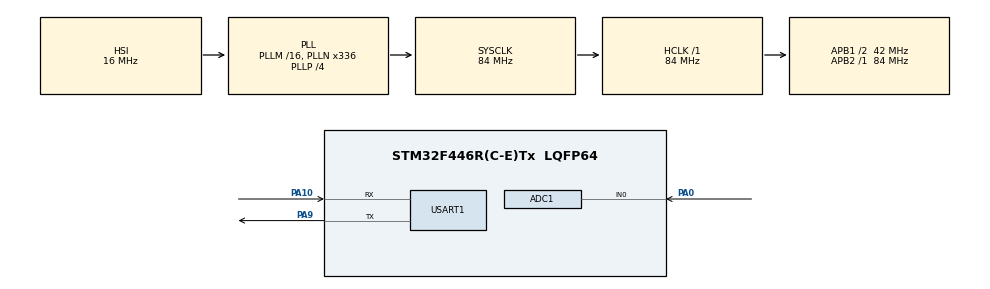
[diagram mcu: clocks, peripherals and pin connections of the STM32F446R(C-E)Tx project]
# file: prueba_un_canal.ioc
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ADC1.Channel-0\#ChannelRegularConversion=ADC_CHANNEL_0
ADC1.NbrOfConversion=1
ADC1.NbrOfConversionFlag=1
ADC1.Rank-0\#ChannelRegularConversion=1
ADC1.SamplingTime-0\#ChannelRegularConversion=ADC_SAMPLETIME_84CYCLES
ADC1.ScanConvMode=DISABLE
ADC1.master=1
Mcu.Family=STM32F4
Mcu.Name=STM32F446R(C-E)Tx
Mcu.Package=LQFP64
NVIC.ADC_IRQn=true\:0\:0\:false\:false\:true\:true
NVIC.PriorityGroup=NVIC_PRIORITYGROUP_0
PA0-WKUP.Signal=ADCx_IN0
PA10.Mode=Asynchronous
PA10.Signal=USART1_RX
PA13.GPIO_Label=TMS
PA13.Mode=Serial_Wire
PA13.Signal=SYS_JTMS-SWDIO
PA14.GPIO_Label=TCK
PA14.Mode=Serial_Wire
PA14.Signal=SYS_JTCK-SWCLK
PA9.Mode=Asynchronous
PA9.Signal=USART1_TX
PB3.GPIO_Label=SWO
PB3.Signal=SYS_JTDO-SWO
PC14-OSC32_IN.Mode=LSE-External-Oscillator
PC14-OSC32_IN.Signal=RCC_OSC32_IN
PC15-OSC32_OUT.Mode=LSE-External-Oscillator
PC15-OSC32_OUT.Signal=RCC_OSC32_OUT
PH0-OSC_IN.Mode=HSE-External-Oscillator
PH0-OSC_IN.Signal=RCC_OSC_IN
PH1-OSC_OUT.Mode=HSE-External-Oscillator
PH1-OSC_OUT.Signal=RCC_OSC_OUT
ProjectManager.HeapSize=0x200
ProjectManager.StackSize=0x400
ProjectManager.TargetToolchain=TrueSTUDIO
RCC.48MHZClocksFreq_Value=84000000
RCC.AHBFreq_Value=84000000
RCC.APB1CLKDivider=RCC_HCLK_DIV2
RCC.APB1Freq_Value=42000000
RCC.APB1TimFreq_Value=84000000
RCC.APB2Freq_Value=84000000
RCC.APB2TimFreq_Value=84000000
RCC.CortexFreq_Value=84000000
RCC.FLatency-AdvancedSettings=FLASH_LATENCY_2
RCC.HCLKFreq_Value=84000000
RCC.HSE_VALUE=8000000
RCC.HSI_VALUE=16000000
RCC.PLLN=336
RCC.PLLP=RCC_PLLP_DIV4
RCC.SYSCLKFreq_VALUE=84000000
RCC.SYSCLKSource=RCC_SYSCLKSOURCE_PLLCLK
RCC.USBFreq_Value=168000000
RCC.VCOOutputFreq_Value=336000000
SH.ADCx_IN0.0=ADC1_IN0,IN0
USART1.VirtualMode=VM_ASYNC
board=NUCLEO-F446RE

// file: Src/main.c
/**
  ******************************************************************************
  * @file           : main.c
  * @brief          : Main program body
  ******************************************************************************
  ** This notice applies to any and all portions of this file
  * that are not between comment pairs USER CODE BEGIN and
  * USER CODE END. Other portions of this file, whether
  * inserted by the user or by software development tools
  * are owned by their respective copyright owners.
  *
  * COPYRIGHT(c) 2018 STMicroelectronics
  *
  * Redistribution and use in source and binary forms, with or without modification,
  * are permitted provided that the following conditions are met:
  *   1. Redistributions of source code must retain the above copyright notice,
  *      this list of conditions and the following disclaimer.
  *   2. Redistributions in binary form must reproduce the above copyright notice,
  *      this list of conditions and the following disclaimer in the documentation
  *      and/or other materials provided with the distribution.
  *   3. Neither the name of STMicroelectronics nor the names of its contributors
  *      may be used to endorse or promote products derived from this software
  *      without specific prior written permission.
  *
  * THIS SOFTWARE IS PROVIDED BY THE COPYRIGHT HOLDERS AND CONTRIBUTORS "AS IS"
  * AND ANY EXPRESS OR IMPLIED WARRANTIES, INCLUDING, BUT NOT LIMITED TO, THE
  * IMPLIED WARRANTIES OF MERCHANTABILITY AND FITNESS FOR A PARTICULAR PURPOSE ARE
  * DISCLAIMED. IN NO EVENT SHALL THE COPYRIGHT HOLDER OR CONTRIBUTORS BE LIABLE
  * FOR ANY DIRECT, INDIRECT, INCIDENTAL, SPECIAL, EXEMPLARY, OR CONSEQUENTIAL
  * DAMAGES (INCLUDING, BUT NOT LIMITED TO, PROCUREMENT OF SUBSTITUTE GOODS OR
  * SERVICES; LOSS OF USE, DATA, OR PROFITS; OR BUSINESS INTERRUPTION) HOWEVER
  * CAUSED AND ON ANY THEORY OF LIABILITY, WHETHER IN CONTRACT, STRICT LIABILITY,
  * OR TORT (INCLUDING NEGLIGENCE OR OTHERWISE) ARISING IN ANY WAY OUT OF THE USE
  * OF THIS SOFTWARE, EVEN IF ADVISED OF THE POSSIBILITY OF SUCH DAMAGE.
  *
  ******************************************************************************
  */
#include "main.h"
#include "stm32f4xx_hal.h"

/* USER CODE BEGIN Includes */
#include <stdio.h>
#include <math.h>
/* USER CODE END Includes */

ADC_HandleTypeDef hadc1;

UART_HandleTypeDef huart1;

/* USER CODE BEGIN PV */
/* Private variables ---------------------------------------------------------*/
uint16_t adc_value;
float voltage;
/* USER CODE END PV */

void SystemClock_Config(void);
static void MX_GPIO_Init(void);
static void MX_ADC1_Init(void);
static void MX_USART1_UART_Init(void);
void ftoa(float n, char *str, int len);

/* USER CODE BEGIN PFP */
/* Private function prototypes -----------------------------------------------*/

/* USER CODE END PFP */
char res[6];
/* USER CODE BEGIN 0 */
void HAL_ADC_ConvCpltCallback(ADC_HandleTypeDef* hadc1)
{
	adc_value = HAL_ADC_GetValue(hadc1);
	 //voltage=3.3000*(adc_value/4096.0000);
	 //ftoa(voltage, res, 3);
	 printf("#%d\r\n",adc_value);
	 //HAL_Delay(1);

	HAL_ADC_Start_IT(hadc1); // Re-Start ADC1 under Interrupt
	                         // this is necessary because we don'use
	                         // the Continuos Conversion Mode
}

/* USER CODE END 0 */

int main(void)
{

  /* MCU Configuration----------------------------------------------------------*/

  /* Reset of all peripherals, Initializes the Flash interface and the Systick. */
  HAL_Init();

  /* Configure the system clock */
  SystemClock_Config();

  /* Initialize all configured peripherals */
  MX_GPIO_Init();
  MX_ADC1_Init();
  MX_USART1_UART_Init();
  /* USER CODE BEGIN 2 */

  HAL_ADC_Start_IT(&hadc1);
  /* USER CODE END 2 */

  /* Infinite loop */
  while (1)
  {

  }

}

void SystemClock_Config(void)
{

  RCC_OscInitTypeDef RCC_OscInitStruct;
  RCC_ClkInitTypeDef RCC_ClkInitStruct;

    /**Configure the main internal regulator output voltage
    */
  __HAL_RCC_PWR_CLK_ENABLE();

  __HAL_PWR_VOLTAGESCALING_CONFIG(PWR_REGULATOR_VOLTAGE_SCALE3);

    /**Initializes the CPU, AHB and APB busses clocks
    */
  RCC_OscInitStruct.OscillatorType = RCC_OSCILLATORTYPE_HSI;
  RCC_OscInitStruct.HSIState = RCC_HSI_ON;
  RCC_OscInitStruct.HSICalibrationValue = 16;
  RCC_OscInitStruct.PLL.PLLState = RCC_PLL_ON;
  RCC_OscInitStruct.PLL.PLLSource = RCC_PLLSOURCE_HSI;
  RCC_OscInitStruct.PLL.PLLM = 16;
  RCC_OscInitStruct.PLL.PLLN = 336;
  RCC_OscInitStruct.PLL.PLLP = RCC_PLLP_DIV4;
  RCC_OscInitStruct.PLL.PLLQ = 2;
  RCC_OscInitStruct.PLL.PLLR = 2;
  if (HAL_RCC_OscConfig(&RCC_OscInitStruct) != HAL_OK)
  {
    _Error_Handler(__FILE__, __LINE__);
  }

    /**Initializes the CPU, AHB and APB busses clocks
    */
  RCC_ClkInitStruct.ClockType = RCC_CLOCKTYPE_HCLK|RCC_CLOCKTYPE_SYSCLK
                              |RCC_CLOCKTYPE_PCLK1|RCC_CLOCKTYPE_PCLK2;
  RCC_ClkInitStruct.SYSCLKSource = RCC_SYSCLKSOURCE_PLLCLK;
  RCC_ClkInitStruct.AHBCLKDivider = RCC_SYSCLK_DIV1;
  RCC_ClkInitStruct.APB1CLKDivider = RCC_HCLK_DIV2;
  RCC_ClkInitStruct.APB2CLKDivider = RCC_HCLK_DIV1;

  if (HAL_RCC_ClockConfig(&RCC_ClkInitStruct, FLASH_LATENCY_2) != HAL_OK)
  {
    _Error_Handler(__FILE__, __LINE__);
  }

    /**Configure the Systick interrupt time
    */
  HAL_SYSTICK_Config(HAL_RCC_GetHCLKFreq()/1000);

    /**Configure the Systick
    */
  HAL_SYSTICK_CLKSourceConfig(SYSTICK_CLKSOURCE_HCLK);

  /* SysTick_IRQn interrupt configuration */
  HAL_NVIC_SetPriority(SysTick_IRQn, 0, 0);
}

/* ADC1 init function */
static void MX_ADC1_Init(void)
{

  ADC_ChannelConfTypeDef sConfig;

    /**Configure the global features of the ADC (Clock, Resolution, Data Alignment and number of conversion)
    */
  hadc1.Instance = ADC1;
  hadc1.Init.ClockPrescaler = ADC_CLOCK_SYNC_PCLK_DIV4;
  hadc1.Init.Resolution = ADC_RESOLUTION_10B;
  hadc1.Init.ScanConvMode = DISABLE;
  hadc1.Init.ContinuousConvMode = DISABLE;
  hadc1.Init.DiscontinuousConvMode = DISABLE;
  hadc1.Init.ExternalTrigConvEdge = ADC_EXTERNALTRIGCONVEDGE_NONE;
  hadc1.Init.ExternalTrigConv = ADC_SOFTWARE_START;
  hadc1.Init.DataAlign = ADC_DATAALIGN_RIGHT;
  hadc1.Init.NbrOfConversion = 1;
  hadc1.Init.DMAContinuousRequests = DISABLE;
  hadc1.Init.EOCSelection = ADC_EOC_SINGLE_CONV;
  if (HAL_ADC_Init(&hadc1) != HAL_OK)
  {
    _Error_Handler(__FILE__, __LINE__);
  }

    /**Configure for the selected ADC regular channel its corresponding rank in the sequencer and its sample time.
    */
  sConfig.Channel = ADC_CHANNEL_0;
  sConfig.Rank = 1;
  sConfig.SamplingTime = ADC_SAMPLETIME_84CYCLES;
  if (HAL_ADC_ConfigChannel(&hadc1, &sConfig) != HAL_OK)
  {
    _Error_Handler(__FILE__, __LINE__);
  }

}

/* USART1 init function */
static void MX_USART1_UART_Init(void)
{

  huart1.Instance = USART1;
  huart1.Init.BaudRate = 115200;
  huart1.Init.WordLength = UART_WORDLENGTH_8B;
  huart1.Init.StopBits = UART_STOPBITS_1;
  huart1.Init.Parity = UART_PARITY_NONE;
  huart1.Init.Mode = UART_MODE_TX_RX;
  huart1.Init.HwFlowCtl = UART_HWCONTROL_NONE;
  huart1.Init.OverSampling = UART_OVERSAMPLING_16;
  if (HAL_UART_Init(&huart1) != HAL_OK)
  {
    _Error_Handler(__FILE__, __LINE__);
  }

}

/** Configure pins as
        * Analog
        * Input
        * Output
        * EVENT_OUT
        * EXTI
*/
static void MX_GPIO_Init(void)
{

  /* GPIO Ports Clock Enable */
  __HAL_RCC_GPIOC_CLK_ENABLE();
  __HAL_RCC_GPIOH_CLK_ENABLE();
  __HAL_RCC_GPIOA_CLK_ENABLE();
  __HAL_RCC_GPIOB_CLK_ENABLE();

}

/* USER CODE BEGIN 4 */
int __io_putchar(int ch)
{
 uint8_t c[1];
 c[0] = ch & 0x00FF;
 HAL_UART_Transmit(&huart1, &*c, 1, 10);
 return ch;
}

int _write(int file,char *ptr, int len)
{
 int DataIdx;
 for(DataIdx= 0; DataIdx< len; DataIdx++)
   {
    __io_putchar(*ptr++);
   }
return len;
}
void reverse(char *str, int len)
{
	int i=0, j=len-1, temp;
	while(i<j)
	{
		temp=str[i];
		str[i]=str[j];
		str[j]=temp;
		i++,j--;
	}
}
int intToStr(int x, char str[], int d)
{
	int i = 0;
	while(x)
	{
		str[i++]=(x%10) + '0';
		x=x/10;
	}

	while(i<d)
		str[i++] = '0';

	reverse(str,i);
	str[i] = '\0';
	return i;
}

void ftoa(float n, char *res, int afterpoint)
{
	int ipart=(int)n;

	float fpart= n - (float)ipart;

	int i = intToStr(ipart, res, 0);

	if(afterpoint != 0)
	{
		res[i] = '.';
		fpart = fpart * pow(10, afterpoint);

		intToStr((int)fpart, res + i + 1, afterpoint);
	}
}
/* USER CODE END 4 */

void _Error_Handler(char *file, int line)
{
  while(1)
  {
  }
}

/************************ (C) COPYRIGHT STMicroelectronics *****END OF FILE****/
